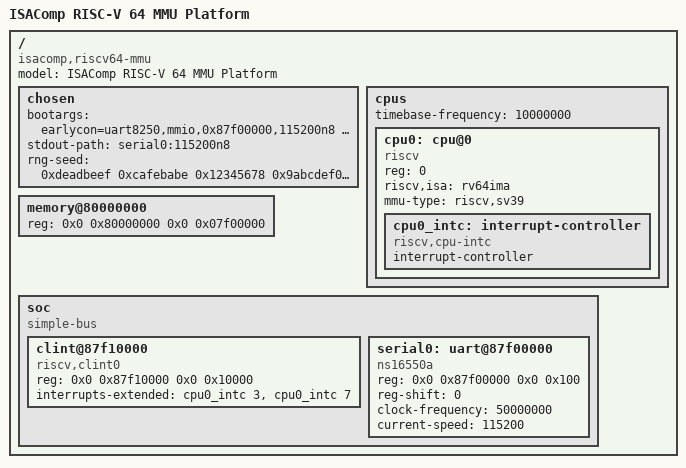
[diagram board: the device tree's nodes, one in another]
/dts-v1/;

/ {
    #address-cells = <2>;
    #size-cells = <2>;
    compatible = "isacomp,riscv64-mmu";
    model = "ISAComp RISC-V 64 MMU Platform";

    chosen {
        bootargs = "earlycon=uart8250,mmio,0x87f00000,115200n8 console=ttyS0 random.trust_bootloader=on";
        stdout-path = "serial0:115200n8";
        rng-seed = <0xdeadbeef 0xcafebabe 0x12345678 0x9abcdef0
                    0xfedcba98 0x76543210 0x0a1b2c3d 0x4e5f6a7b>;
    };

    cpus {
        #address-cells = <1>;
        #size-cells = <0>;
        timebase-frequency = <10000000>;  // 10 MHz timer

        cpu0: cpu@0 {
            device_type = "cpu";
            reg = <0>;
            compatible = "riscv";
            riscv,isa = "rv64ima";
            mmu-type = "riscv,sv39";

            cpu0_intc: interrupt-controller {
                #interrupt-cells = <1>;
                interrupt-controller;
                compatible = "riscv,cpu-intc";
            };
        };
    };

    memory@80000000 {
        device_type = "memory";
        reg = <0x0 0x80000000 0x0 0x07f00000>;  // 127MB at 0x80000000 (last 1MB reserved for peripherals)
    };

    soc {
        #address-cells = <2>;
        #size-cells = <2>;
        compatible = "simple-bus";
        ranges;

        clint@87f10000 {
            compatible = "riscv,clint0";
            reg = <0x0 0x87f10000 0x0 0x10000>;  // In reserved last 1MB
            interrupts-extended = <&cpu0_intc 3 &cpu0_intc 7>;  // M-mode SW and timer
        };

        serial0: uart@87f00000 {
            compatible = "ns16550a";
            reg = <0x0 0x87f00000 0x0 0x100>;  // In reserved last 1MB
            reg-shift = <0>;
            clock-frequency = <50000000>;  // 50 MHz
            current-speed = <115200>;
            // No interrupts for now - polling mode
        };
    };
};
